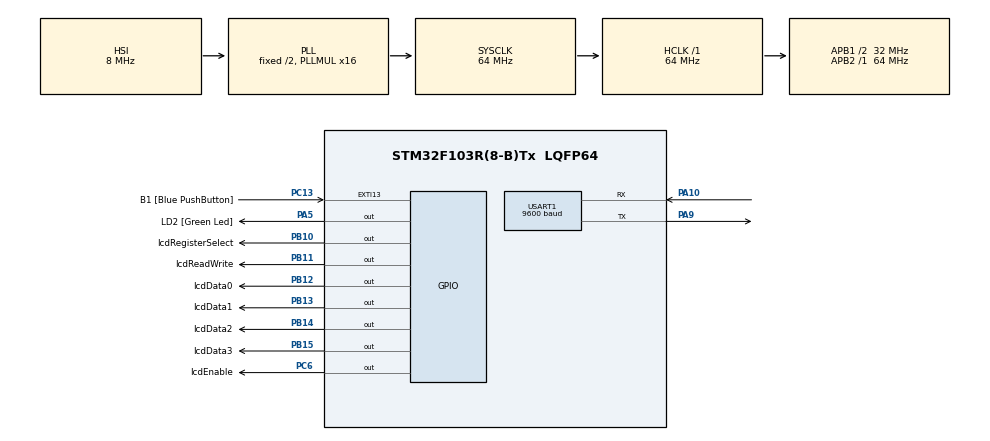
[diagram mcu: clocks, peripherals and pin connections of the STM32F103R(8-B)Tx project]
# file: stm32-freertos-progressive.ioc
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FREERTOS.BinarySemaphores01=DistanceReadySemaphore,Dynamic,NULL,Depleted
FREERTOS.Mutexes01=lcdMutex,Dynamic,NULL,Available
FREERTOS.Queues01=lcdQueue,1,LCD_MSG_SIZE,0,Dynamic,NULL,NULL
FREERTOS.Tasks01=LEDBlinkTask,24,128,StartLEDBlinkTask,Default,NULL,Dynamic,NULL,NULL;USARTTask,24,128,StartUSARTTask,Default,NULL,Dynamic,NULL,NULL;LCDTask,24,128,StartLCDTask,Default,NULL,Dynamic,NULL,NULL;EmergencyTask,40,128,StartEmergencyTask,Default,NULL,Dynamic,NULL,NULL;DstSensorTask,24,128,StartDistanceSensorTask,Default,NULL,Dynamic,NULL,NULL
FREERTOS.Timers01=LedHeartbeatTimer,App_LedTimerCallback,osTimerPeriodic,Default,NULL,Dynamic,NULL
FREERTOS.configTOTAL_HEAP_SIZE=4098
Mcu.Family=STM32F1
Mcu.Name=STM32F103R(8-B)Tx
Mcu.Package=LQFP64
Mcu.UserConstants=LCD_MSG_SIZE,messageQueue_t;LCD_MSG_DATA_SIZE,32
NVIC.EXTI15_10_IRQn=true\:5\:0\:false\:false\:true\:true\:true\:true\:true
NVIC.PriorityGroup=NVIC_PRIORITYGROUP_4
NVIC.TIM4_IRQn=true\:15\:0\:false\:false\:true\:false\:false\:true\:true
NVIC.TimeBase=TIM4_IRQn
NVIC.TimeBaseIP=TIM4
NVIC.USART1_IRQn=true\:5\:0\:false\:false\:true\:true\:true\:true\:true
PA10.Mode=Asynchronous
PA10.Signal=USART1_RX
PA13.GPIO_Label=TMS
PA13.Mode=Serial_Wire
PA13.Signal=SYS_JTMS-SWDIO
PA14.GPIO_Label=TCK
PA14.Mode=Serial_Wire
PA14.Signal=SYS_JTCK-SWCLK
PA2.GPIO_Label=USART_TX
PA2.GPIO_Mode=GPIO_MODE_AF_PP
PA2.GPIO_PuPd=GPIO_NOPULL
PA2.GPIO_Speed=GPIO_SPEED_FREQ_LOW
PA2.Signal=USART2_TX
PA5.GPIO_Label=LD2 [Green Led]
PA5.GPIO_ModeDefaultOutputPP=GPIO_MODE_OUTPUT_PP
PA5.GPIO_PuPd=GPIO_NOPULL
PA5.GPIO_Speed=GPIO_SPEED_FREQ_LOW
PA5.Signal=GPIO_Output
PA9.Mode=Asynchronous
PA9.Signal=USART1_TX
PB10.GPIO_Label=lcdRegisterSelect
PB10.Signal=GPIO_Output
PB11.GPIO_Label=lcdReadWrite
PB11.Signal=GPIO_Output
PB12.GPIO_Label=lcdData0
PB12.GPIO_PuPd=GPIO_NOPULL
PB12.Signal=GPIO_Output
PB13.GPIO_Label=lcdData1
PB13.Signal=GPIO_Output
PB14.GPIO_Label=lcdData2
PB14.Signal=GPIO_Output
PB15.GPIO_Label=lcdData3
PB15.Signal=GPIO_Output
PB3.GPIO_Label=SWO
PB3.Signal=SYS_JTDO-TRACESWO
PC13-TAMPER-RTC.GPIO_Label=B1 [Blue PushButton]
PC13-TAMPER-RTC.GPIO_ModeDefaultEXTI=GPIO_MODE_IT_FALLING
PC13-TAMPER-RTC.GPIO_PuPd=GPIO_PULLDOWN
PC13-TAMPER-RTC.Signal=GPXTI13
PC14-OSC32_IN.Signal=RCC_OSC32_IN
PC15-OSC32_OUT.Signal=RCC_OSC32_OUT
PC6.GPIO_Label=lcdEnable
PC6.GPIO_Speed=GPIO_SPEED_FREQ_HIGH
PC6.Signal=GPIO_Output
PD0-OSC_IN.Signal=RCC_OSC_IN
PD1-OSC_OUT.Signal=RCC_OSC_OUT
ProjectManager.HeapSize=0x200
ProjectManager.StackSize=0x400
ProjectManager.TargetToolchain=CMake
RCC.ADCPresc=RCC_ADCPCLK2_DIV8
RCC.AHBFreq_Value=64000000
RCC.APB1CLKDivider=RCC_HCLK_DIV2
RCC.APB1Freq_Value=32000000
RCC.APB1TimFreq_Value=64000000
RCC.APB2Freq_Value=64000000
RCC.APB2TimFreq_Value=64000000
RCC.HCLKFreq_Value=64000000
RCC.PLLMUL=RCC_PLL_MUL16
RCC.SYSCLKFreq_VALUE=64000000
RCC.SYSCLKSource=RCC_SYSCLKSOURCE_PLLCLK
RCC.USBFreq_Value=64000000
USART1.BaudRate=9600
USART1.VirtualMode=VM_ASYNC
VP_FREERTOS_VS_CMSIS_V2.Mode=CMSIS_V2
VP_SYS_VS_tim4.Mode=TIM4
board=NUCLEO-F103RB

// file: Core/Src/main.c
/* USER CODE BEGIN Header */
/**
 ******************************************************************************
 * @file           : main.c
 * @brief          : Main program body
 ******************************************************************************
 * @attention
 *
 * Copyright (c) 2026 STMicroelectronics.
 * All rights reserved.
 *
 * This software is licensed under terms that can be found in the LICENSE file
 * in the root directory of this software component.
 * If no LICENSE file comes with this software, it is provided AS-IS.
 *
 ******************************************************************************
 */
/* USER CODE END Header */
#include "main.h"
#include "cmsis_os.h"

/* USER CODE BEGIN Includes */
#include "app_tasks.h"
/* USER CODE END Includes */

/* USER CODE BEGIN PTD */
messageQueue_t msg = {0};
/* USER CODE END PTD */

UART_HandleTypeDef huart1;

/* Definitions for LEDBlinkTask */
osThreadId_t LEDBlinkTaskHandle;
const osThreadAttr_t LEDBlinkTask_attributes = {
    .name = "LEDBlinkTask",
    .stack_size = 128 * 4,
    .priority = (osPriority_t)osPriorityNormal,
};
/* Definitions for USARTTask */
osThreadId_t USARTTaskHandle;
const osThreadAttr_t USARTTask_attributes = {
    .name = "USARTTask",
    .stack_size = 128 * 4,
    .priority = (osPriority_t)osPriorityNormal,
};
/* Definitions for LCDTask */
osThreadId_t LCDTaskHandle;
const osThreadAttr_t LCDTask_attributes = {
    .name = "LCDTask",
    .stack_size = 128 * 4,
    .priority = (osPriority_t)osPriorityNormal,
};
/* Definitions for EmergencyTask */
osThreadId_t EmergencyTaskHandle;
const osThreadAttr_t EmergencyTask_attributes = {
    .name = "EmergencyTask",
    .stack_size = 128 * 4,
    .priority = (osPriority_t)osPriorityHigh,
};
/* Definitions for DstSensorTask */
osThreadId_t DstSensorTaskHandle;
const osThreadAttr_t DstSensorTask_attributes = {
    .name = "DstSensorTask",
    .stack_size = 128 * 4,
    .priority = (osPriority_t)osPriorityNormal,
};
/* Definitions for lcdQueue */
osMessageQueueId_t lcdQueueHandle;
const osMessageQueueAttr_t lcdQueue_attributes = {
    .name = "lcdQueue"};
/* Definitions for LedHeartbeatTimer */
osTimerId_t LedHeartbeatTimerHandle;
const osTimerAttr_t LedHeartbeatTimer_attributes = {
    .name = "LedHeartbeatTimer"};
/* Definitions for lcdMutex */
osMutexId_t lcdMutexHandle;
const osMutexAttr_t lcdMutex_attributes = {
    .name = "lcdMutex"};
/* Definitions for DistanceReadySemaphore */
osSemaphoreId_t DistanceReadySemaphoreHandle;
const osSemaphoreAttr_t DistanceReadySemaphore_attributes = {
    .name = "DistanceReadySemaphore"};
/* USER CODE BEGIN PV */
uint8_t uartData[32] = {0};
uint16_t adcData[2] = {0};
/* USER CODE END PV */

void SystemClock_Config(void);
static void MX_GPIO_Init(void);
static void MX_USART1_UART_Init(void);
void StartLEDBlinkTask(void *argument);
void StartUSARTTask(void *argument);
void StartLCDTask(void *argument);
void StartEmergencyTask(void *argument);
void StartDistanceSensorTask(void *argument);
void App_LedTimerCallback(void *argument);

int main(void)
{

  /* MCU Configuration--------------------------------------------------------*/

  /* Reset of all peripherals, Initializes the Flash interface and the Systick. */
  HAL_Init();

  /* Configure the system clock */
  SystemClock_Config();

  /* Initialize all configured peripherals */
  MX_GPIO_Init();
  MX_USART1_UART_Init();

  /* Init scheduler */
  osKernelInitialize();
  /* Create the mutex(es) */
  /* creation of lcdMutex */
  lcdMutexHandle = osMutexNew(&lcdMutex_attributes);

  /* Create the semaphores(s) */
  /* creation of DistanceReadySemaphore */
  DistanceReadySemaphoreHandle = osSemaphoreNew(1, 0, &DistanceReadySemaphore_attributes);

  /* Create the timer(s) */
  /* creation of LedHeartbeatTimer */
  LedHeartbeatTimerHandle = osTimerNew(App_LedTimerCallback, osTimerPeriodic, NULL, &LedHeartbeatTimer_attributes);

  /* USER CODE BEGIN RTOS_TIMERS */
  if (osTimerStart(LedHeartbeatTimerHandle, 500U) != osOK)
  {
    Error_Handler();
  }
  /* USER CODE END RTOS_TIMERS */

  /* Create the queue(s) */
  /* creation of lcdQueue */
  lcdQueueHandle = osMessageQueueNew(1, sizeof(LCD_MSG_SIZE), &lcdQueue_attributes);

  /* Create the thread(s) */
  /* creation of LEDBlinkTask */
  LEDBlinkTaskHandle = osThreadNew(StartLEDBlinkTask, NULL, &LEDBlinkTask_attributes);

  /* creation of USARTTask */
  USARTTaskHandle = osThreadNew(StartUSARTTask, NULL, &USARTTask_attributes);

  /* creation of LCDTask */
  LCDTaskHandle = osThreadNew(StartLCDTask, NULL, &LCDTask_attributes);

  /* creation of EmergencyTask */
  EmergencyTaskHandle = osThreadNew(StartEmergencyTask, NULL, &EmergencyTask_attributes);

  /* creation of DstSensorTask */
  DstSensorTaskHandle = osThreadNew(StartDistanceSensorTask, NULL, &DstSensorTask_attributes);

  /* Start scheduler */
  osKernelStart();

  /* We should never get here as control is now taken by the scheduler */

  /* Infinite loop */
  while (1)
  {

  }
}

void SystemClock_Config(void)
{
  RCC_OscInitTypeDef RCC_OscInitStruct = {0};
  RCC_ClkInitTypeDef RCC_ClkInitStruct = {0};

  /** Initializes the RCC Oscillators according to the specified parameters
   * in the RCC_OscInitTypeDef structure.
   */
  RCC_OscInitStruct.OscillatorType = RCC_OSCILLATORTYPE_HSI;
  RCC_OscInitStruct.HSIState = RCC_HSI_ON;
  RCC_OscInitStruct.HSICalibrationValue = RCC_HSICALIBRATION_DEFAULT;
  RCC_OscInitStruct.PLL.PLLState = RCC_PLL_ON;
  RCC_OscInitStruct.PLL.PLLSource = RCC_PLLSOURCE_HSI_DIV2;
  RCC_OscInitStruct.PLL.PLLMUL = RCC_PLL_MUL16;
  if (HAL_RCC_OscConfig(&RCC_OscInitStruct) != HAL_OK)
  {
    Error_Handler();
  }

  /** Initializes the CPU, AHB and APB buses clocks
   */
  RCC_ClkInitStruct.ClockType = RCC_CLOCKTYPE_HCLK | RCC_CLOCKTYPE_SYSCLK | RCC_CLOCKTYPE_PCLK1 | RCC_CLOCKTYPE_PCLK2;
  RCC_ClkInitStruct.SYSCLKSource = RCC_SYSCLKSOURCE_PLLCLK;
  RCC_ClkInitStruct.AHBCLKDivider = RCC_SYSCLK_DIV1;
  RCC_ClkInitStruct.APB1CLKDivider = RCC_HCLK_DIV2;
  RCC_ClkInitStruct.APB2CLKDivider = RCC_HCLK_DIV1;

  if (HAL_RCC_ClockConfig(&RCC_ClkInitStruct, FLASH_LATENCY_2) != HAL_OK)
  {
    Error_Handler();
  }
}

static void MX_USART1_UART_Init(void)
{

  huart1.Instance = USART1;
  huart1.Init.BaudRate = 9600;
  huart1.Init.WordLength = UART_WORDLENGTH_8B;
  huart1.Init.StopBits = UART_STOPBITS_1;
  huart1.Init.Parity = UART_PARITY_NONE;
  huart1.Init.Mode = UART_MODE_TX_RX;
  huart1.Init.HwFlowCtl = UART_HWCONTROL_NONE;
  huart1.Init.OverSampling = UART_OVERSAMPLING_16;
  if (HAL_UART_Init(&huart1) != HAL_OK)
  {
    Error_Handler();
  }
}

static void MX_GPIO_Init(void)
{
  GPIO_InitTypeDef GPIO_InitStruct = {0};

  /* GPIO Ports Clock Enable */
  __HAL_RCC_GPIOC_CLK_ENABLE();
  __HAL_RCC_GPIOD_CLK_ENABLE();
  __HAL_RCC_GPIOA_CLK_ENABLE();
  __HAL_RCC_GPIOB_CLK_ENABLE();

  /*Configure GPIO pin Output Level */
  HAL_GPIO_WritePin(LD2_GPIO_Port, LD2_Pin, GPIO_PIN_RESET);

  /*Configure GPIO pin Output Level */
  HAL_GPIO_WritePin(GPIOB, lcdRegisterSelect_Pin | lcdReadWrite_Pin | lcdData0_Pin | lcdData1_Pin | lcdData2_Pin | lcdData3_Pin, GPIO_PIN_RESET);

  /*Configure GPIO pin Output Level */
  HAL_GPIO_WritePin(lcdEnable_GPIO_Port, lcdEnable_Pin, GPIO_PIN_RESET);

  /*Configure GPIO pin : B1_Pin */
  GPIO_InitStruct.Pin = B1_Pin;
  GPIO_InitStruct.Mode = GPIO_MODE_IT_FALLING;
  GPIO_InitStruct.Pull = GPIO_PULLDOWN;
  HAL_GPIO_Init(B1_GPIO_Port, &GPIO_InitStruct);

  /*Configure GPIO pin : USART_TX_Pin */
  GPIO_InitStruct.Pin = USART_TX_Pin;
  GPIO_InitStruct.Mode = GPIO_MODE_AF_PP;
  GPIO_InitStruct.Speed = GPIO_SPEED_FREQ_LOW;
  HAL_GPIO_Init(USART_TX_GPIO_Port, &GPIO_InitStruct);

  /*Configure GPIO pin : LD2_Pin */
  GPIO_InitStruct.Pin = LD2_Pin;
  GPIO_InitStruct.Mode = GPIO_MODE_OUTPUT_PP;
  GPIO_InitStruct.Pull = GPIO_NOPULL;
  GPIO_InitStruct.Speed = GPIO_SPEED_FREQ_LOW;
  HAL_GPIO_Init(LD2_GPIO_Port, &GPIO_InitStruct);

  /*Configure GPIO pins : lcdRegisterSelect_Pin lcdReadWrite_Pin lcdData0_Pin lcdData1_Pin
                           lcdData2_Pin lcdData3_Pin */
  GPIO_InitStruct.Pin = lcdRegisterSelect_Pin | lcdReadWrite_Pin | lcdData0_Pin | lcdData1_Pin | lcdData2_Pin | lcdData3_Pin;
  GPIO_InitStruct.Mode = GPIO_MODE_OUTPUT_PP;
  GPIO_InitStruct.Pull = GPIO_NOPULL;
  GPIO_InitStruct.Speed = GPIO_SPEED_FREQ_LOW;
  HAL_GPIO_Init(GPIOB, &GPIO_InitStruct);

  /*Configure GPIO pin : lcdEnable_Pin */
  GPIO_InitStruct.Pin = lcdEnable_Pin;
  GPIO_InitStruct.Mode = GPIO_MODE_OUTPUT_PP;
  GPIO_InitStruct.Pull = GPIO_NOPULL;
  GPIO_InitStruct.Speed = GPIO_SPEED_FREQ_HIGH;
  HAL_GPIO_Init(lcdEnable_GPIO_Port, &GPIO_InitStruct);

  /* EXTI interrupt init*/
  HAL_NVIC_SetPriority(EXTI15_10_IRQn, 5, 0);
  HAL_NVIC_EnableIRQ(EXTI15_10_IRQn);

}

void StartLEDBlinkTask(void *argument)
{
  /* USER CODE BEGIN 5 */
  App_LEDBlinkTask(argument);
  /* USER CODE END 5 */
}

void StartUSARTTask(void *argument)
{
  /* USER CODE BEGIN StartUSARTTask */
  App_USARTTask(argument);
  /* USER CODE END StartUSARTTask */
}

void StartLCDTask(void *argument)
{
  /* USER CODE BEGIN StartLCDTask */
  App_LCDTask(argument);
  /* USER CODE END StartLCDTask */
}

void StartEmergencyTask(void *argument)
{
  /* USER CODE BEGIN StartEmergencyTask */
  App_EmergencyTask(argument);
  /* USER CODE END StartEmergencyTask */
}

void StartDistanceSensorTask(void *argument)
{
  /* USER CODE BEGIN StartDistanceSensorTask */
  App_DistanceSensorTask(argument);
  /* USER CODE END StartDistanceSensorTask */
}

/* App_LedTimerCallback function */
void App_LedTimerCallback(void *argument)
{
  /* USER CODE BEGIN App_LedTimerCallback */
  App_LedTimerCallbackImpl(argument);
  /* USER CODE END App_LedTimerCallback */
}

void HAL_TIM_PeriodElapsedCallback(TIM_HandleTypeDef *htim)
{
  if (htim->Instance == TIM4)
  {
    HAL_IncTick();
  }
}

void Error_Handler(void)
{
  __disable_irq();
  while (1)
  {
  }
}
